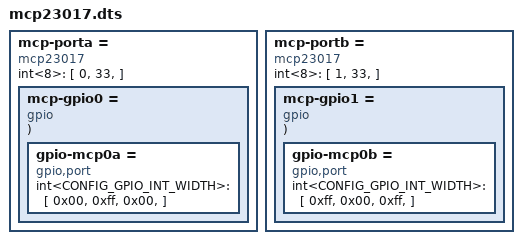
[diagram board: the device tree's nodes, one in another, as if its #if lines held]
/**
 * Copyright (C) 2022 Jan Nowotsch
 * Author Jan Nowotsch	<jan.nowotsch@gmail.com>
 *
 * Released under the terms of the GNU GPL v2.0
 */



#include <config/config.h>
#include <gpio.dts>


mcp-porta = {
	compatible = "mcp23017";

	/* mcp23017 port config (dt_data_t) */
	int<8> = [
		0,			// port (a)
		33,			// slave address
	];

	mcp-gpio0 = {
		compatible = "gpio";

		gpio_cfg_t(
			0x00,	// in_mask
			0xff,	// out_mask
			0x00,	// int_mask
			0xff,	// invert_mask
			0		// interrupt
		);

		gpio-mcp0a = {
			compatible = "gpio,port";

			/* port config (gpio_port_cfg_t) */
			int<CONFIG_GPIO_INT_WIDTH> = [
				0x00,	// in_mask
				0xff,	// out_mask
				0x00,	// int_mask
			];
		};
	};
};

mcp-portb = {
	compatible = "mcp23017";

	/* mcp23017 port config (dt_data_t) */
	int<8> = [
		1,				// port (b)
		33,				// slave address
	];

	mcp-gpio1 = {
		compatible = "gpio";

		gpio_cfg_t(
			0xff,		// in mask
			0x00,		// out mask
			0xff,		// int mask
			0xff,		// invert mask
#ifdef CONFIG_GPIO_INTFWD
			mcp-int.int[1]	// interrupt
#else
			0
#endif // CONFIG_GPIO_INTFWD
		);

		gpio-mcp0b = {
			compatible = "gpio,port";

			/* port config (gpio_port_cfg_t) */
			int<CONFIG_GPIO_INT_WIDTH> = [
				0xff,	// in mask
				0x00,	// out mask
				0xff,	// int mask
			];
		};
	};
};
